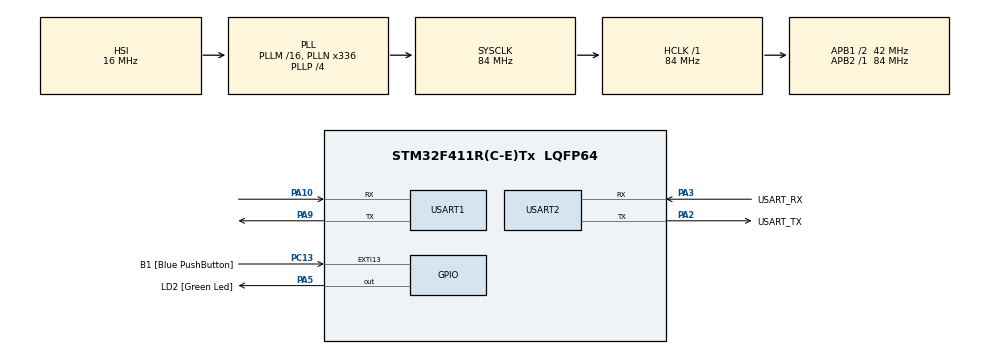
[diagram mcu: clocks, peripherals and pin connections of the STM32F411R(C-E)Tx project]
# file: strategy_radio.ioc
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Dma.Request0=USART2_RX
Dma.Request1=USART2_TX
Dma.Request2=USART1_RX
Dma.Request3=USART1_TX
Dma.USART1_RX.2.Direction=DMA_PERIPH_TO_MEMORY
Dma.USART1_RX.2.FIFOMode=DMA_FIFOMODE_DISABLE
Dma.USART1_RX.2.Instance=DMA2_Stream2
Dma.USART1_RX.2.MemDataAlignment=DMA_MDATAALIGN_BYTE
Dma.USART1_RX.2.MemInc=DMA_MINC_ENABLE
Dma.USART1_RX.2.Mode=DMA_CIRCULAR
Dma.USART1_RX.2.PeriphDataAlignment=DMA_PDATAALIGN_BYTE
Dma.USART1_RX.2.PeriphInc=DMA_PINC_DISABLE
Dma.USART1_RX.2.Priority=DMA_PRIORITY_HIGH
Dma.USART1_TX.3.Direction=DMA_MEMORY_TO_PERIPH
Dma.USART1_TX.3.FIFOMode=DMA_FIFOMODE_DISABLE
Dma.USART1_TX.3.Instance=DMA2_Stream7
Dma.USART1_TX.3.MemDataAlignment=DMA_MDATAALIGN_BYTE
Dma.USART1_TX.3.MemInc=DMA_MINC_ENABLE
Dma.USART1_TX.3.Mode=DMA_NORMAL
Dma.USART1_TX.3.PeriphDataAlignment=DMA_PDATAALIGN_BYTE
Dma.USART1_TX.3.PeriphInc=DMA_PINC_DISABLE
Dma.USART1_TX.3.Priority=DMA_PRIORITY_HIGH
Dma.USART2_RX.0.Direction=DMA_PERIPH_TO_MEMORY
Dma.USART2_RX.0.FIFOMode=DMA_FIFOMODE_DISABLE
Dma.USART2_RX.0.Instance=DMA1_Stream5
Dma.USART2_RX.0.MemDataAlignment=DMA_MDATAALIGN_BYTE
Dma.USART2_RX.0.MemInc=DMA_MINC_ENABLE
Dma.USART2_RX.0.Mode=DMA_CIRCULAR
Dma.USART2_RX.0.PeriphDataAlignment=DMA_PDATAALIGN_BYTE
Dma.USART2_RX.0.PeriphInc=DMA_PINC_DISABLE
Dma.USART2_RX.0.Priority=DMA_PRIORITY_HIGH
Dma.USART2_TX.1.Direction=DMA_MEMORY_TO_PERIPH
Dma.USART2_TX.1.FIFOMode=DMA_FIFOMODE_DISABLE
Dma.USART2_TX.1.Instance=DMA1_Stream6
Dma.USART2_TX.1.MemDataAlignment=DMA_MDATAALIGN_BYTE
Dma.USART2_TX.1.MemInc=DMA_MINC_ENABLE
Dma.USART2_TX.1.Mode=DMA_NORMAL
Dma.USART2_TX.1.PeriphDataAlignment=DMA_PDATAALIGN_BYTE
Dma.USART2_TX.1.PeriphInc=DMA_PINC_DISABLE
Dma.USART2_TX.1.Priority=DMA_PRIORITY_HIGH
FREERTOS.Tasks01=defaultTask,0,128,StartDefaultTask,Default,NULL,Dynamic,NULL,NULL
FREERTOS.configUSE_NEWLIB_REENTRANT=1
Mcu.Family=STM32F4
Mcu.Name=STM32F411R(C-E)Tx
Mcu.Package=LQFP64
NVIC.DMA1_Stream5_IRQn=true\:5\:0\:false\:false\:true\:false\:false\:true\:true
NVIC.DMA1_Stream6_IRQn=true\:5\:0\:false\:false\:true\:true\:false\:true\:true
NVIC.DMA2_Stream2_IRQn=true\:5\:0\:false\:false\:true\:true\:false\:true\:true
NVIC.DMA2_Stream7_IRQn=true\:5\:0\:false\:false\:true\:true\:false\:true\:true
NVIC.PriorityGroup=NVIC_PRIORITYGROUP_4
NVIC.TIM2_IRQn=true\:15\:0\:false\:false\:true\:false\:false\:true\:true
NVIC.TimeBase=TIM2_IRQn
NVIC.TimeBaseIP=TIM2
NVIC.USART2_IRQn=true\:5\:0\:false\:false\:true\:true\:true\:true\:true
PA10.Mode=Asynchronous
PA10.Signal=USART1_RX
PA13.GPIO_Label=TMS
PA13.Mode=Serial_Wire
PA13.Signal=SYS_JTMS-SWDIO
PA14.GPIO_Label=TCK
PA14.Mode=Serial_Wire
PA14.Signal=SYS_JTCK-SWCLK
PA2.GPIO_Label=USART_TX
PA2.Mode=Asynchronous
PA2.Signal=USART2_TX
PA3.GPIO_Label=USART_RX
PA3.Mode=Asynchronous
PA3.Signal=USART2_RX
PA5.GPIO_Label=LD2 [Green Led]
PA5.Signal=GPIO_Output
PA9.Mode=Asynchronous
PA9.Signal=USART1_TX
PB3.GPIO_Label=SWO
PB3.Signal=SYS_JTDO-SWO
PC13-ANTI_TAMP.GPIO_Label=B1 [Blue PushButton]
PC13-ANTI_TAMP.GPIO_ModeDefaultEXTI=GPIO_MODE_IT_FALLING
PC13-ANTI_TAMP.Signal=GPXTI13
PC14-OSC32_IN.Mode=LSE-External-Oscillator
PC14-OSC32_IN.Signal=RCC_OSC32_IN
PC15-OSC32_OUT.Mode=LSE-External-Oscillator
PC15-OSC32_OUT.Signal=RCC_OSC32_OUT
PH0\ -\ OSC_IN.Mode=HSE-External-Clock-Source
PH0\ -\ OSC_IN.Signal=RCC_OSC_IN
PH1\ -\ OSC_OUT.Mode=HSE-External-Clock-Source
PH1\ -\ OSC_OUT.Signal=RCC_OSC_OUT
ProjectManager.HeapSize=0x200
ProjectManager.StackSize=0x400
ProjectManager.TargetToolchain=STM32CubeIDE
RCC.48MHZClocksFreq_Value=84000000
RCC.AHBFreq_Value=84000000
RCC.APB1CLKDivider=RCC_HCLK_DIV2
RCC.APB1Freq_Value=42000000
RCC.APB1TimFreq_Value=84000000
RCC.APB2Freq_Value=84000000
RCC.APB2TimFreq_Value=84000000
RCC.CortexFreq_Value=84000000
RCC.FLatency-AdvancedSettings=FLASH_LATENCY_2
RCC.HCLKFreq_Value=84000000
RCC.HSE_VALUE=8000000
RCC.HSI_VALUE=16000000
RCC.PLLN=336
RCC.PLLP=RCC_PLLP_DIV4
RCC.SYSCLKFreq_VALUE=84000000
RCC.SYSCLKSource=RCC_SYSCLKSOURCE_PLLCLK
RCC.VCOOutputFreq_Value=336000000
USART1.VirtualMode=VM_ASYNC
USART2.VirtualMode=VM_ASYNC
VP_CRC_VS_CRC.Mode=CRC_Activate
VP_FREERTOS_VS_CMSIS_V1.Mode=CMSIS_V1
VP_SYS_VS_tim2.Mode=TIM2
board=NUCLEO-F411RE

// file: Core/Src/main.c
/* USER CODE BEGIN Header */
/**
  ******************************************************************************
  * @file           : main.c
  * @brief          : Main program body
  ******************************************************************************
  * @attention
  *
  * Copyright (c) 2023 STMicroelectronics.
  * All rights reserved.
  *
  * This software is licensed under terms that can be found in the LICENSE file
  * in the root directory of this software component.
  * If no LICENSE file comes with this software, it is provided AS-IS.
  *
  ******************************************************************************
  */
/* USER CODE END Header */
#include "main.h"
#include "cmsis_os.h"

/* USER CODE BEGIN Includes */
#include "btcp.h"
/* USER CODE END Includes */

 CRC_HandleTypeDef hcrc;

UART_HandleTypeDef huart1;
UART_HandleTypeDef huart2;
DMA_HandleTypeDef hdma_usart1_rx;
DMA_HandleTypeDef hdma_usart1_tx;
DMA_HandleTypeDef hdma_usart2_rx;
DMA_HandleTypeDef hdma_usart2_tx;

osThreadId defaultTaskHandle;
/* USER CODE BEGIN PV */
B_tcpHandle_t* btcp;
B_uartHandle_t* buart;

B_tcpHandle_t* btcp_uart1;
B_uartHandle_t* buart_uart1;
/* USER CODE END PV */

void SystemClock_Config(void);
static void MX_GPIO_Init(void);
static void MX_DMA_Init(void);
static void MX_USART2_UART_Init(void);
static void MX_CRC_Init(void);
static void MX_USART1_UART_Init(void);
void StartDefaultTask(void const * argument);

int main(void)
{

  /* MCU Configuration--------------------------------------------------------*/

  /* Reset of all peripherals, Initializes the Flash interface and the Systick. */
  HAL_Init();

  /* Configure the system clock */
  SystemClock_Config();

  /* Initialize all configured peripherals */
  MX_GPIO_Init();
  MX_DMA_Init();
  MX_USART2_UART_Init();
  MX_CRC_Init();
  MX_USART1_UART_Init();

  /* USER CODE BEGIN RTOS_QUEUES */
  /* add queues, ... */

#ifdef DEFAULT_TASK
  /* USER CODE END RTOS_QUEUES */

  /* Create the thread(s) */
  /* definition and creation of defaultTask */
  osThreadDef(defaultTask, StartDefaultTask, osPriorityNormal, 0, 128);
  defaultTaskHandle = osThreadCreate(osThread(defaultTask), NULL);

  /* USER CODE BEGIN RTOS_THREADS */
#endif
  /* add threads, ... */
	buart = B_uartStart(&huart2);
	btcp = B_tcpStart(SENDER_ID_NOT_USED, &buart, buart, 1, &hcrc);

	buart_uart1 = B_uartStart(&huart2);
	btcp_uart1 = B_tcpStart(SENDER_ID_NOT_USED, &buart_uart1, buart, 1, &hcrc); // Set transmit uart to buart to forwared received data to uart1
  /* USER CODE END RTOS_THREADS */

  /* Start scheduler */
  osKernelStart();

  /* We should never get here as control is now taken by the scheduler */
  /* Infinite loop */
  while (1)
  {

  }
}

void SystemClock_Config(void)
{
  RCC_OscInitTypeDef RCC_OscInitStruct = {0};
  RCC_ClkInitTypeDef RCC_ClkInitStruct = {0};

  /** Configure the main internal regulator output voltage
  */
  __HAL_RCC_PWR_CLK_ENABLE();
  __HAL_PWR_VOLTAGESCALING_CONFIG(PWR_REGULATOR_VOLTAGE_SCALE1);

  /** Initializes the RCC Oscillators according to the specified parameters
  * in the RCC_OscInitTypeDef structure.
  */
  RCC_OscInitStruct.OscillatorType = RCC_OSCILLATORTYPE_HSI;
  RCC_OscInitStruct.HSIState = RCC_HSI_ON;
  RCC_OscInitStruct.HSICalibrationValue = RCC_HSICALIBRATION_DEFAULT;
  RCC_OscInitStruct.PLL.PLLState = RCC_PLL_ON;
  RCC_OscInitStruct.PLL.PLLSource = RCC_PLLSOURCE_HSI;
  RCC_OscInitStruct.PLL.PLLM = 16;
  RCC_OscInitStruct.PLL.PLLN = 336;
  RCC_OscInitStruct.PLL.PLLP = RCC_PLLP_DIV4;
  RCC_OscInitStruct.PLL.PLLQ = 4;
  if (HAL_RCC_OscConfig(&RCC_OscInitStruct) != HAL_OK)
  {
    Error_Handler();
  }

  /** Initializes the CPU, AHB and APB buses clocks
  */
  RCC_ClkInitStruct.ClockType = RCC_CLOCKTYPE_HCLK|RCC_CLOCKTYPE_SYSCLK
                              |RCC_CLOCKTYPE_PCLK1|RCC_CLOCKTYPE_PCLK2;
  RCC_ClkInitStruct.SYSCLKSource = RCC_SYSCLKSOURCE_PLLCLK;
  RCC_ClkInitStruct.AHBCLKDivider = RCC_SYSCLK_DIV1;
  RCC_ClkInitStruct.APB1CLKDivider = RCC_HCLK_DIV2;
  RCC_ClkInitStruct.APB2CLKDivider = RCC_HCLK_DIV1;

  if (HAL_RCC_ClockConfig(&RCC_ClkInitStruct, FLASH_LATENCY_2) != HAL_OK)
  {
    Error_Handler();
  }
}

static void MX_CRC_Init(void)
{

  hcrc.Instance = CRC;
  if (HAL_CRC_Init(&hcrc) != HAL_OK)
  {
    Error_Handler();
  }

}

static void MX_USART1_UART_Init(void)
{

  huart1.Instance = USART1;
  huart1.Init.BaudRate = 115200;
  huart1.Init.WordLength = UART_WORDLENGTH_8B;
  huart1.Init.StopBits = UART_STOPBITS_1;
  huart1.Init.Parity = UART_PARITY_NONE;
  huart1.Init.Mode = UART_MODE_TX_RX;
  huart1.Init.HwFlowCtl = UART_HWCONTROL_NONE;
  huart1.Init.OverSampling = UART_OVERSAMPLING_16;
  if (HAL_UART_Init(&huart1) != HAL_OK)
  {
    Error_Handler();
  }

}

static void MX_USART2_UART_Init(void)
{

  huart2.Instance = USART2;
  huart2.Init.BaudRate = 115200;
  huart2.Init.WordLength = UART_WORDLENGTH_8B;
  huart2.Init.StopBits = UART_STOPBITS_1;
  huart2.Init.Parity = UART_PARITY_NONE;
  huart2.Init.Mode = UART_MODE_TX_RX;
  huart2.Init.HwFlowCtl = UART_HWCONTROL_NONE;
  huart2.Init.OverSampling = UART_OVERSAMPLING_16;
  if (HAL_UART_Init(&huart2) != HAL_OK)
  {
    Error_Handler();
  }

}

static void MX_DMA_Init(void)
{

  /* DMA controller clock enable */
  __HAL_RCC_DMA1_CLK_ENABLE();
  __HAL_RCC_DMA2_CLK_ENABLE();

  /* DMA interrupt init */
  /* DMA1_Stream5_IRQn interrupt configuration */
  HAL_NVIC_SetPriority(DMA1_Stream5_IRQn, 5, 0);
  HAL_NVIC_EnableIRQ(DMA1_Stream5_IRQn);
  /* DMA1_Stream6_IRQn interrupt configuration */
  HAL_NVIC_SetPriority(DMA1_Stream6_IRQn, 5, 0);
  HAL_NVIC_EnableIRQ(DMA1_Stream6_IRQn);
  /* DMA2_Stream2_IRQn interrupt configuration */
  HAL_NVIC_SetPriority(DMA2_Stream2_IRQn, 5, 0);
  HAL_NVIC_EnableIRQ(DMA2_Stream2_IRQn);
  /* DMA2_Stream7_IRQn interrupt configuration */
  HAL_NVIC_SetPriority(DMA2_Stream7_IRQn, 5, 0);
  HAL_NVIC_EnableIRQ(DMA2_Stream7_IRQn);

}

static void MX_GPIO_Init(void)
{
  GPIO_InitTypeDef GPIO_InitStruct = {0};

  /* GPIO Ports Clock Enable */
  __HAL_RCC_GPIOC_CLK_ENABLE();
  __HAL_RCC_GPIOH_CLK_ENABLE();
  __HAL_RCC_GPIOA_CLK_ENABLE();
  __HAL_RCC_GPIOB_CLK_ENABLE();

  /*Configure GPIO pin Output Level */
  HAL_GPIO_WritePin(LD2_GPIO_Port, LD2_Pin, GPIO_PIN_RESET);

  /*Configure GPIO pin : B1_Pin */
  GPIO_InitStruct.Pin = B1_Pin;
  GPIO_InitStruct.Mode = GPIO_MODE_IT_FALLING;
  GPIO_InitStruct.Pull = GPIO_NOPULL;
  HAL_GPIO_Init(B1_GPIO_Port, &GPIO_InitStruct);

  /*Configure GPIO pin : LD2_Pin */
  GPIO_InitStruct.Pin = LD2_Pin;
  GPIO_InitStruct.Mode = GPIO_MODE_OUTPUT_PP;
  GPIO_InitStruct.Pull = GPIO_NOPULL;
  GPIO_InitStruct.Speed = GPIO_SPEED_FREQ_LOW;
  HAL_GPIO_Init(LD2_GPIO_Port, &GPIO_InitStruct);

}

void StartDefaultTask(void const * argument)
{
  for(;;)
  {
    osDelay(1);
  }
}

void HAL_TIM_PeriodElapsedCallback(TIM_HandleTypeDef *htim)
{
  if (htim->Instance == TIM2) {
    HAL_IncTick();
  }
}

void Error_Handler(void)
{
  __disable_irq();
  while (1)
  {
  }
}
